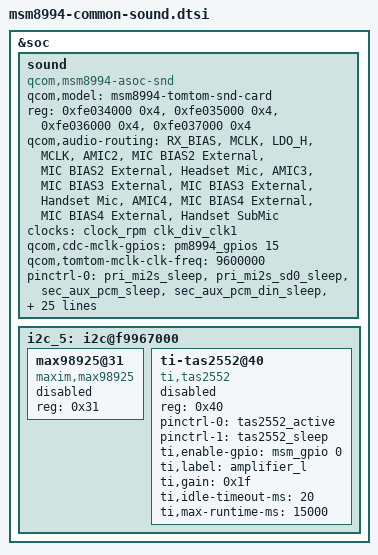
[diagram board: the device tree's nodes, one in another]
/* Copyright (c) 2014, The Linux Foundation. All rights reserved.
 *
 * This program is free software; you can redistribute it and/or modify
 * it under the terms of the GNU General Public License version 2 and
 * only version 2 as published by the Free Software Foundation.
 *
 * This program is distributed in the hope that it will be useful,
 * but WITHOUT ANY WARRANTY; without even the implied warranty of
 * MERCHANTABILITY or FITNESS FOR A PARTICULAR PURPOSE.  See the
 * GNU General Public License for more details.
 */

&soc {
	sound {
		compatible = "qcom,msm8994-asoc-snd";
		qcom,model = "msm8994-tomtom-snd-card";
		reg = <0xfe034000 0x4>,
		      <0xfe035000 0x4>,
		      <0xfe036000 0x4>,
		      <0xfe037000 0x4>;
		reg-names = "lpaif_pri_mode_muxsel",
			    "lpaif_sec_mode_muxsel",
			    "lpaif_tert_mode_muxsel",
			    "lpaif_quat_mode_muxsel";

		qcom,audio-routing =
			"RX_BIAS", "MCLK",
			"LDO_H", "MCLK",
			"AMIC2", "MIC BIAS2 External",
			"MIC BIAS2 External", "Headset Mic",
			"AMIC3", "MIC BIAS3 External",
			"MIC BIAS3 External", "Handset Mic",
			"AMIC4", "MIC BIAS4 External",
			"MIC BIAS4 External", "Handset SubMic";

		clock-names = "osr_clk";
		clocks = <&clock_rpm clk_div_clk1>;
		qcom,cdc-mclk-gpios = <&pm8994_gpios 15 0>;
		qcom,tomtom-mclk-clk-freq = <9600000>;
		pinctrl-names = "sleep",
			"active",
			"pri_mi2s-active",
			"auxpcm-active",
			"quat_mi2s-active";
		pinctrl-0 = <&pri_mi2s_sleep>, <&pri_mi2s_sd0_sleep>, <&sec_aux_pcm_sleep>, <&sec_aux_pcm_din_sleep>, <&quat_mi2s_sleep>, <&quat_mi2s_mclk_sleep>, <&quat_mi2s_sd0_sleep> , <&quat_mi2s_sd1_sleep>;
		pinctrl-1 = <&pri_mi2s_active>, <&pri_mi2s_sd0_active>, <&sec_aux_pcm_active>, <&sec_aux_pcm_din_active>, <&quat_mi2s_active>, <&quat_mi2s_mclk_active>, <&quat_mi2s_sd0_active> , <&quat_mi2s_sd1_active>;
		pinctrl-2 = <&sec_aux_pcm_sleep>, <&sec_aux_pcm_din_sleep>, <&quat_mi2s_sleep>, <&quat_mi2s_mclk_sleep>, <&quat_mi2s_sd0_sleep> , <&quat_mi2s_sd1_sleep>,
		            <&pri_mi2s_active>, <&pri_mi2s_sd0_active>;		    
		pinctrl-3 = <&pri_mi2s_sleep>, <&pri_mi2s_sd0_sleep>, <&quat_mi2s_sleep>, <&quat_mi2s_mclk_sleep>, <&quat_mi2s_sd0_sleep> , <&quat_mi2s_sd1_sleep>,
		            <&sec_aux_pcm_active>, <&sec_aux_pcm_din_active>;
        pinctrl-4 = <&pri_mi2s_sleep>, <&pri_mi2s_sd0_sleep>, <&sec_aux_pcm_sleep>, <&sec_aux_pcm_din_sleep>,
                    <&quat_mi2s_active>, <&quat_mi2s_mclk_active>, <&quat_mi2s_sd0_active> , <&quat_mi2s_sd1_active>;

		qcom,cdc-micbias2-headset-only;
/*		qcom,us-euro-gpios = <&pm8994_mpps 2 0>;   */
/*		qcom,mbhc-audio-jack-type = "4-pole-jack"; */
		qcom,hdmi-audio-rx;
		asoc-codec = <&stub_codec>, <&hdmi_audio>;
		asoc-codec-names = "msm-stub-codec.1", "msm-hdmi-audio-codec-rx";
	};

	i2c_5: i2c@f9967000 {
		max98925@31 {
			status = "disabled";
			reg = <0x31>;
			compatible = "maxim,max98925";
		};

		ti-tas2552@40 {
			compatible = "ti,tas2552";
			status = "disabled";
			reg = <0x40>;
			pinctrl-names = "default", "sleep";
			pinctrl-0 = <&tas2552_active>;
			pinctrl-1 = <&tas2552_sleep>;
			ti,enable-gpio = <&msm_gpio 0 0>;
			ti,label = "amplifier_l";
			ti,gain = <0x1f>;
			ti,idle-timeout-ms = <20>;
			ti,max-runtime-ms = <15000>;
		};

	};
};
